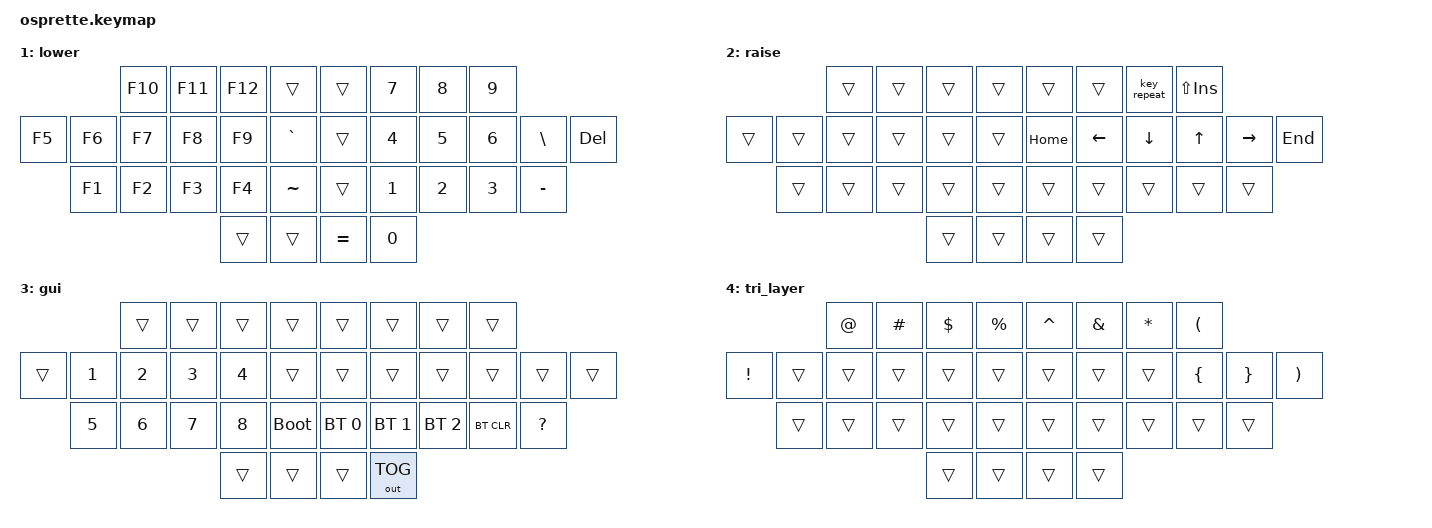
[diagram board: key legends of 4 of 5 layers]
/*
* Copyright (c) 2021 The ZMK Contributors
*
* SPDX-License-Identifier: MIT
*/

#include <behaviors.dtsi>
#include <dt-bindings/zmk/keys.h>
#include <dt-bindings/zmk/bt.h>
#include <dt-bindings/zmk/outputs.h>

// Home row mods macro
#define HRML(k1,k2,k3,k4) &ht LSHFT k1  &ht LALT k2  &ht LCTRL k3  &ht LGUI k4
#define HRMR(k1,k2,k3,k4) &ht RGUI k1  &ht RCTRL k2  &ht RALT k3  &ht RSHFT k4

//#define HRMS(k1) &ht LSHFT

/ {
    macros {
    /**
    * Temporarily switches to a layer (`&mo`) while a modifier is held.
    * Analogous to QMK's `LM()`, using a parameterized macro.
    *
    * Params:
    *  1. Layer to switch to
    *  2. Modifier to press while layer is active
    *
    * Example:
    *  `&lm NUM_LAYER LSHIFT`
    */
    lm: lm {
        label = "LAYER_MOD";
        compatible = "zmk,behavior-macro-two-param";
        wait-ms = <0>;
        tap-ms = <0>;
        #binding-cells = <2>;
        bindings
            = <&macro_param_1to1>
            , <&macro_press &mo MACRO_PLACEHOLDER>
            , <&macro_param_2to1>
            , <&macro_press &kp MACRO_PLACEHOLDER>
            , <&macro_pause_for_release>
            , <&macro_param_2to1>
            , <&macro_release &kp MACRO_PLACEHOLDER>
            , <&macro_param_1to1>
            , <&macro_release &mo MACRO_PLACEHOLDER>
            ;
        };
    };

    combos {
        compatible = "zmk,combos";
        combo_jk {
            timeout-ms = <100>;
            key-positions = <22 23>;
            bindings = <&kp ESC>;
        };
        combo_qj {
            timeout-ms = <100>;
            key-positions = <21 22>;
            bindings = <&kp ESC>;
        };
        combo_esc {
            timeout-ms = <100>;
            key-positions = <0 1>;
            bindings = <&kp ESC>;
        };
        combo_delete_word {
            timeout-ms = <100>;
            key-positions = <8 9>;
            bindings = <&kp LC(BSPC)>;
        };
        combo_slsh {
            timeout-ms = <100>;
            key-positions = <18 19>;
            bindings = <&kp SLASH>;
        };
        combo_enter {
            timeout-ms = <100>;
            key-positions = <16 18>;
            bindings = <&kp ENTER>;
        };
        combo_enter_alt {
            timeout-ms = <130>;
            key-positions = <16 17>;
            bindings = <&kp ENTER>;
        };
        combo_shift {
            timeout-ms = <100>;
            key-positions = <30 33>;
            bindings = <&kp LSHIFT>;
        };
        combo_scln {
            timeout-ms = <100>;
            key-positions = <20 21>;
            bindings = <&kp SEMICOLON>;
        };
    };

    behaviors {
        ht: hold_tap {
            label = "hold_tap";
            compatible = "zmk,behavior-hold-tap";
            #binding-cells = <2>;
            flavor = "balanced";
            tapping-term-ms = <220>;
            quick-tap-ms = <150>;
            global-quick-tap;
            bindings = <&kp>, <&kp>;
        };
    };

    conditional_layers {
        compatible = "zmk,conditional-layers";
        tri_layer {
            if-layers = <1 2>;
            then-layer = <4>;
        };
    };

    keymap {
        compatible = "zmk,keymap";
        default_layer {
            bindings = <
                                  &kp COMMA  &kp DOT    &kp P      &kp Y                     &kp F      &kp G      &kp C      &kp R
            &kp SQT    HRML(A,        O,         E,         U)     &kp I          &kp D      HRMR(H,        T,         N,         S)     &kp L
                       &kp COLON  &kp Q      &kp J      &kp K      &kp X          &kp B      &kp M      &kp W      &kp V      &kp Z
                                                     &lm 3 LGUI  &lt 1 BSPC     &lt 2 SPACE  &mt LCTL TAB
            >;
        };

        lower {
            bindings = <
                                  &kp F10    &kp F11    &kp F12    &trans         &trans     &kp N7     &kp N8     &kp N9
            &kp F5     &kp F6     &kp F7     &kp F8     &kp F9     &kp GRAVE      &trans     &kp N4     &kp N5     &kp N6     &kp BSLH      &kp DEL
                       &kp F1     &kp F2     &kp F3     &kp F4     &kp TILDE      &trans     &kp N1     &kp N2     &kp N3     &kp MINUS
                                                        &trans     &trans         &kp EQUAL  &kp N0
            >;
        };

        raise {
            bindings = <
                                  &trans     &trans     &trans     &trans         &trans     &trans     &key_repeat &kp LS(INS)
            &trans     &trans     &trans     &trans     &trans     &trans         &kp HOME   &kp LEFT   &kp DOWN    &kp UP      &kp RIGHT  &kp END
                       &trans     &trans     &trans     &trans     &trans         &trans     &trans     &trans      &trans      &trans
                                                        &trans     &trans         &trans     &trans
            >;
        };

        gui {
            bindings = <
                                  &trans     &trans     &trans     &trans        &trans     &trans     &trans     &trans
            &trans     &kp N1     &kp N2     &kp N3     &kp N4     &trans        &trans     &trans     &trans     &trans     &trans     &trans
                       &kp N5     &kp N6     &kp N7     &kp N8     &bootloader   &bt BT_SEL 0 &bt BT_SEL 1 &bt BT_SEL 2 &bt BT_CLR &kp QMARK
                                                        &trans     &trans        &trans     &out OUT_TOG
            >;
        };

        tri_layer {
            bindings = <
                                  &kp AT     &kp HASH   &kp DLLR  &kp PRCNT       &kp CARET  &kp AMPS   &kp STAR   &kp LPAR
            &kp EXCL   &trans     &trans     &trans     &trans    &trans          &trans     &trans     &trans     &kp LBRC  &kp RBRC &kp RPAR
                       &trans     &trans     &trans     &trans    &trans          &trans     &trans     &trans     &trans    &trans
                                                        &trans    &trans          &trans     &trans
            >;
        };
    };
};
